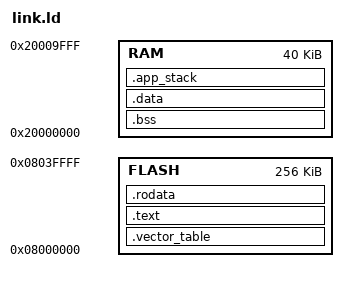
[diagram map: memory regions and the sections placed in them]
MEMORY
{
  /* NOTE 1 K = 1 KiBi = 1024 bytes */
  /* TODO Adjust these memory regions to match your device memory layout */
  /* These values correspond to the LM3S6965, one of the few devices QEMU can emulate */
  FLASH : ORIGIN = 0x08000000, LENGTH = 256K
  RAM : ORIGIN = 0x20000000, LENGTH = 40K
}

/* The entry point is the reset handler */
ENTRY(Reset);

SECTIONS
{
  .vector_table ORIGIN(FLASH) :
  {
    LONG(ORIGIN(RAM) + LENGTH(RAM));

    KEEP(*(.vector_table));
  } > FLASH

  .text :
  {
    *(.text .text.*);
  } > FLASH

  .rodata :
  {
    *(.rodata .rodata.*);
  } > FLASH

  .bss (NOLOAD):
  {
    _sbss = .;
    *(.bss .bss.*);
    _ebss = .;
  } > RAM

  .data : AT(ADDR(.rodata) + SIZEOF(.rodata))
  {
    _sdata = .;
    *(.data .data.*);
    _edata = .;
  } > RAM

  _sidata = LOADADDR(.data);

  .app_stack ALIGN(0x08):
  {
    *(.app_stack .app_stack.*);
  } > RAM

  /DISCARD/ :
  {
    *(.ARM.exidx .ARM.exidx.*);
  }
}

PROVIDE(NMI = DefaultExceptionHandler);
PROVIDE(HardFault = DefaultExceptionHandler);
PROVIDE(MemManage = DefaultExceptionHandler);
PROVIDE(BusFault = DefaultExceptionHandler);
PROVIDE(UsageFault = DefaultExceptionHandler);
PROVIDE(SVCall = DefaultExceptionHandler);
PROVIDE(PendSV = DefaultExceptionHandler);
PROVIDE(SysTick = DefaultExceptionHandler);
